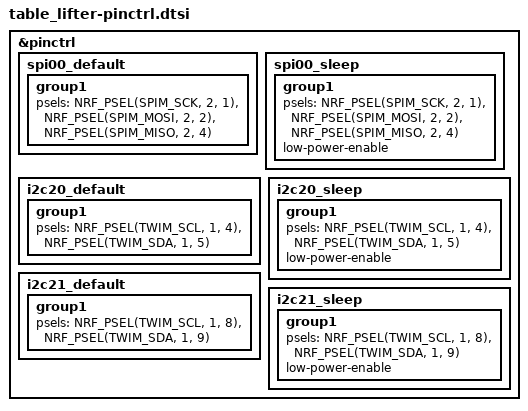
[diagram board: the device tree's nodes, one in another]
#include <zephyr/dt-bindings/pinctrl/nrf-pinctrl.h>
&pinctrl {
  spi00_default: spi00_default { group1 { psels = <NRF_PSEL(SPIM_SCK, 2, 1)>, <NRF_PSEL(SPIM_MOSI, 2, 2)>, <NRF_PSEL(SPIM_MISO, 2, 4)>; }; };
  spi00_sleep: spi00_sleep { group1 { psels = <NRF_PSEL(SPIM_SCK, 2, 1)>, <NRF_PSEL(SPIM_MOSI, 2, 2)>, <NRF_PSEL(SPIM_MISO, 2, 4)>; low-power-enable; }; };
  i2c20_default: i2c20_default { group1 { psels = <NRF_PSEL(TWIM_SCL, 1, 4)>, <NRF_PSEL(TWIM_SDA, 1, 5)>; }; };
  i2c20_sleep: i2c20_sleep { group1 { psels = <NRF_PSEL(TWIM_SCL, 1, 4)>, <NRF_PSEL(TWIM_SDA, 1, 5)>; low-power-enable; }; };
  i2c21_default: i2c21_default { group1 { psels = <NRF_PSEL(TWIM_SCL, 1, 8)>, <NRF_PSEL(TWIM_SDA, 1, 9)>; }; };
  i2c21_sleep: i2c21_sleep { group1 { psels = <NRF_PSEL(TWIM_SCL, 1, 8)>, <NRF_PSEL(TWIM_SDA, 1, 9)>; low-power-enable; }; };
};
